# PCIE_PWR_REGS register map
Vendor: Texas Instruments
Peripheral module from a debugger description file (folder 66AK2G0x_66AK2G1x).
Registers are 32-bit, read-only, reset values left out (the file's numbers can be read two ways) unless marked. A register's access mark holds for its fields unless they carry their own. Offsets are as the file gives them; lines under a group give offsets from that group; [hi:lo] are bit positions; {n}, {i} and the like mark numbered series; 'fields as' and 'values as' point back to an identical list; <NAME> marks a mode.

## PCIE_PWR_REGS
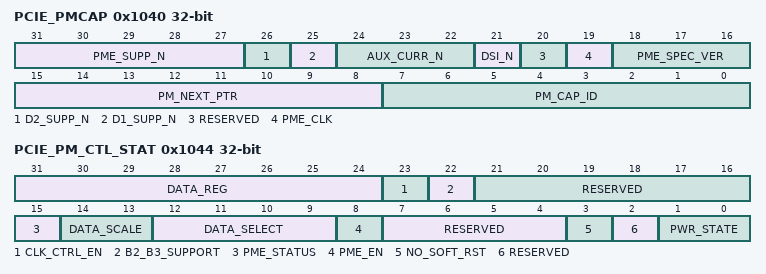
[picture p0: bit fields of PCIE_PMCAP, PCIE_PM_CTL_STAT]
0x1040 PCIE_PMCAP
  [31:27] PME_SUPP_N — PME Support. Identifies the power states from which generates PME Messages. A value of 0 for any bit indicates that the device (or function) is not capable of generating PME Messages while in that power state. Writable from internal bus interface.
  [26] D2_SUPP_N — D2 Support. Writable from internal bus interface.
  [25] D1_SUPP_N — D1 Support. Writable from internal bus interface.
  [24:22] AUX_CURR_N — Auxiliary Current. Writable from internal bus interface.
  [21] DSI_N — Device Specific Initialization. Writable from internal bus interface.
  [20] RESERVED — Reads return 0 and writes have no effect.
  [19] PME_CLK — PME Clock. Hardwired to zero.
  [18:16] PME_SPEC_VER — Power Management Specification Version. Writable from internal bus interface.
  [15:8] PM_NEXT_PTR — Next capability pointer. By default, it points to Message Signaled Interrupt structure.Writable from internal bus interface.
  [7:0] PM_CAP_ID — Power Management Capability ID.
0x1044 PCIE_PM_CTL_STAT access not given
  [31:24] DATA_REG ro — Data register for additional information. Not supported.
  [23] CLK_CTRL_EN ro — Bus Power/Clock Control Enable. Hardwired to zero.
  [22] B2_B3_SUPPORT ro — B2 and B3 support. Hardwired to zero.
  [21:16] RESERVED ro — Reads return 0 and writes have no effect.
  [15] PME_STATUS — PME Status. Indicates if a previously enabled PME event occurred or not. (access RW1C)
  [14:13] DATA_SCALE ro — Data Scale. Not supported.
  [12:9] DATA_SELECT ro — Data Select. Not supported.
  [8] PME_EN rw — PME Enable. Value of 1 indicates device is enabled to generate PME. Writable from internal bus interface.
  [7:4] RESERVED ro — Reads return 0 and writes have no effect.
  [3] NO_SOFT_RST ro — No Soft Reset. It is set to disable reset during a transition from D3 to D0. Writable from internal bus interface.
  [2] RESERVED ro — Reads return 0 and writes have no effect.
  [1:0] PWR_STATE rw — Power State. Controls the device power state. Writes are ignored if the state is not supported. Writable from internal bus interface.
